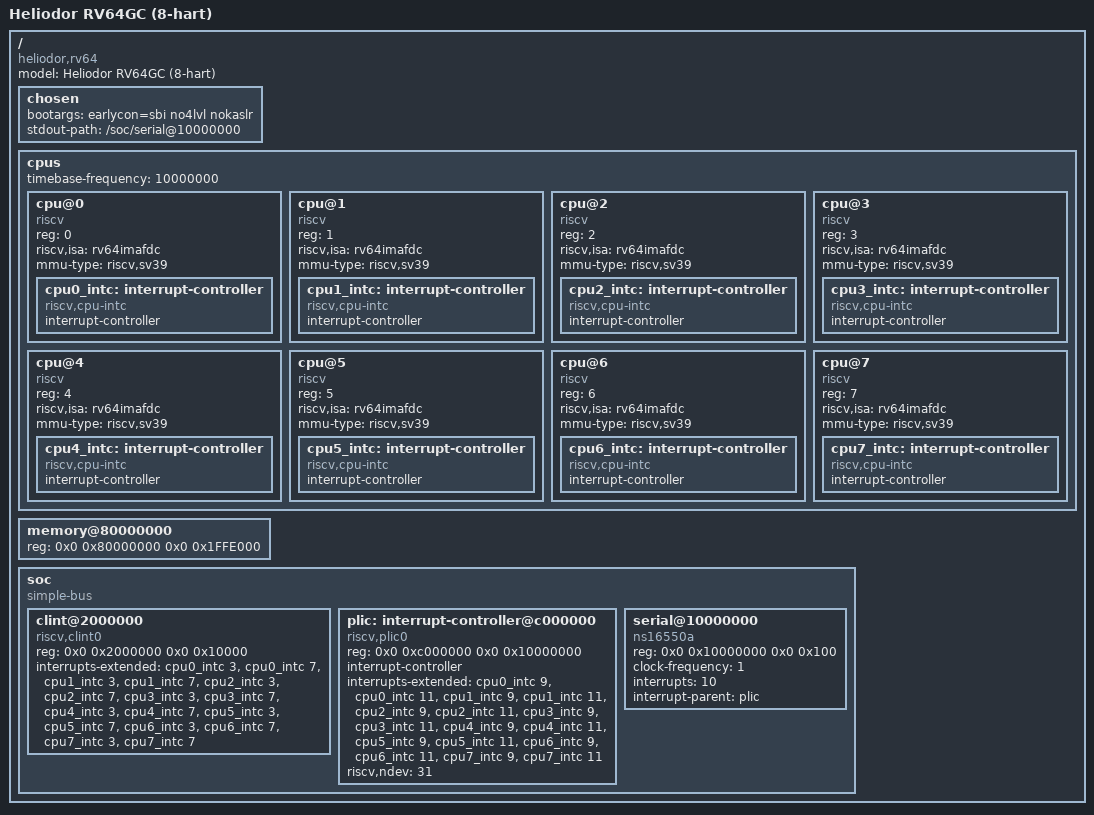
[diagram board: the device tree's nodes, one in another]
/dts-v1/;

/ {
	#address-cells = <2>;
	#size-cells = <2>;
	compatible = "heliodor,rv64";
	model = "Heliodor RV64GC (8-hart)";

	chosen {
		bootargs = "earlycon=sbi no4lvl nokaslr";
		stdout-path = "/soc/serial@10000000";
	};

	cpus {
		#address-cells = <1>;
		#size-cells = <0>;
		timebase-frequency = <10000000>;

		cpu@0 {
			device_type = "cpu";
			compatible = "riscv";
			reg = <0>;
			riscv,isa = "rv64imafdc";
			mmu-type = "riscv,sv39";
			status = "okay";
			cpu0_intc: interrupt-controller {
				#interrupt-cells = <1>;
				compatible = "riscv,cpu-intc";
				interrupt-controller;
			};
		};

		cpu@1 {
			device_type = "cpu";
			compatible = "riscv";
			reg = <1>;
			riscv,isa = "rv64imafdc";
			mmu-type = "riscv,sv39";
			status = "okay";
			cpu1_intc: interrupt-controller {
				#interrupt-cells = <1>;
				compatible = "riscv,cpu-intc";
				interrupt-controller;
			};
		};

		cpu@2 {
			device_type = "cpu";
			compatible = "riscv";
			reg = <2>;
			riscv,isa = "rv64imafdc";
			mmu-type = "riscv,sv39";
			status = "okay";
			cpu2_intc: interrupt-controller {
				#interrupt-cells = <1>;
				compatible = "riscv,cpu-intc";
				interrupt-controller;
			};
		};

		cpu@3 {
			device_type = "cpu";
			compatible = "riscv";
			reg = <3>;
			riscv,isa = "rv64imafdc";
			mmu-type = "riscv,sv39";
			status = "okay";
			cpu3_intc: interrupt-controller {
				#interrupt-cells = <1>;
				compatible = "riscv,cpu-intc";
				interrupt-controller;
			};
		};

		cpu@4 {
			device_type = "cpu";
			compatible = "riscv";
			reg = <4>;
			riscv,isa = "rv64imafdc";
			mmu-type = "riscv,sv39";
			status = "okay";
			cpu4_intc: interrupt-controller {
				#interrupt-cells = <1>;
				compatible = "riscv,cpu-intc";
				interrupt-controller;
			};
		};

		cpu@5 {
			device_type = "cpu";
			compatible = "riscv";
			reg = <5>;
			riscv,isa = "rv64imafdc";
			mmu-type = "riscv,sv39";
			status = "okay";
			cpu5_intc: interrupt-controller {
				#interrupt-cells = <1>;
				compatible = "riscv,cpu-intc";
				interrupt-controller;
			};
		};

		cpu@6 {
			device_type = "cpu";
			compatible = "riscv";
			reg = <6>;
			riscv,isa = "rv64imafdc";
			mmu-type = "riscv,sv39";
			status = "okay";
			cpu6_intc: interrupt-controller {
				#interrupt-cells = <1>;
				compatible = "riscv,cpu-intc";
				interrupt-controller;
			};
		};

		cpu@7 {
			device_type = "cpu";
			compatible = "riscv";
			reg = <7>;
			riscv,isa = "rv64imafdc";
			mmu-type = "riscv,sv39";
			status = "okay";
			cpu7_intc: interrupt-controller {
				#interrupt-cells = <1>;
				compatible = "riscv,cpu-intc";
				interrupt-controller;
			};
		};
	};

	memory@80000000 {
		device_type = "memory";
		/* DRAM = 32MB - 8KB. Top 8KB reserved for firmware's per-hart
		 * scratch (0x81FFE000 + 0x100*hartid, up to hart 7 = 0x81FFE700)
		 * and per-hart mscratch (0x81FFF000 - 0x80*hartid, down to hart 7
		 * = 0x81FFEC80). Both fit in the 8KB carveout; same as 2/4-hart. */
		reg = <0x0 0x80000000 0x0 0x1FFE000>;
	};

	soc {
		#address-cells = <2>;
		#size-cells = <2>;
		compatible = "simple-bus";
		ranges;

		clint@2000000 {
			compatible = "riscv,clint0";
			reg = <0x0 0x2000000 0x0 0x10000>;
			interrupts-extended = <&cpu0_intc 3>, <&cpu0_intc 7>,
			                      <&cpu1_intc 3>, <&cpu1_intc 7>,
			                      <&cpu2_intc 3>, <&cpu2_intc 7>,
			                      <&cpu3_intc 3>, <&cpu3_intc 7>,
			                      <&cpu4_intc 3>, <&cpu4_intc 7>,
			                      <&cpu5_intc 3>, <&cpu5_intc 7>,
			                      <&cpu6_intc 3>, <&cpu6_intc 7>,
			                      <&cpu7_intc 3>, <&cpu7_intc 7>;
		};

		plic: interrupt-controller@c000000 {
			compatible = "riscv,plic0";
			reg = <0x0 0xc000000 0x0 0x10000000>;
			#interrupt-cells = <1>;
			interrupt-controller;
			interrupts-extended = <&cpu0_intc 9>, <&cpu0_intc 11>,
			                      <&cpu1_intc 9>, <&cpu1_intc 11>,
			                      <&cpu2_intc 9>, <&cpu2_intc 11>,
			                      <&cpu3_intc 9>, <&cpu3_intc 11>,
			                      <&cpu4_intc 9>, <&cpu4_intc 11>,
			                      <&cpu5_intc 9>, <&cpu5_intc 11>,
			                      <&cpu6_intc 9>, <&cpu6_intc 11>,
			                      <&cpu7_intc 9>, <&cpu7_intc 11>;
			riscv,ndev = <31>;
		};

		serial@10000000 {
			compatible = "ns16550a";
			reg = <0x0 0x10000000 0x0 0x100>;
			clock-frequency = <1>;
			interrupts = <10>;
			interrupt-parent = <&plic>;
		};
	};
};
